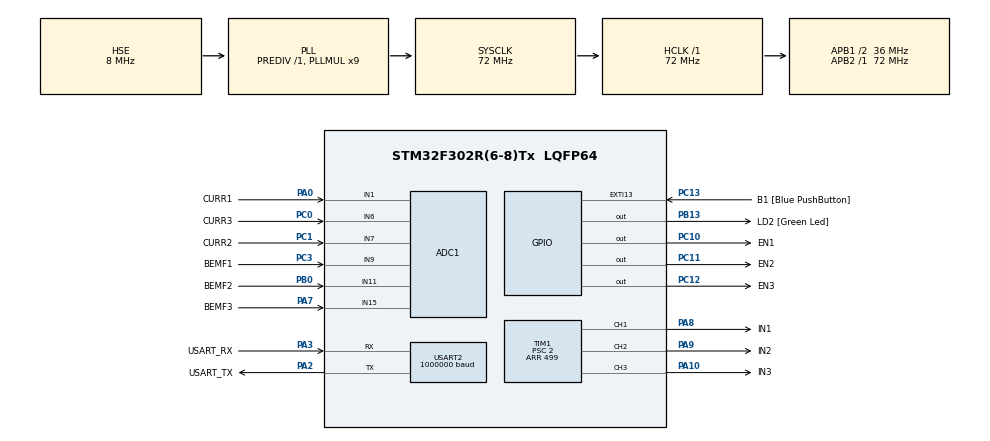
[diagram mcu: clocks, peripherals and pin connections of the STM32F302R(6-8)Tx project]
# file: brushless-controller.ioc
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ADC1.Channel-0\#ChannelRegularConversion=ADC_CHANNEL_9
ADC1.Channel-1\#ChannelRegularConversion=ADC_CHANNEL_11
ADC1.Channel-2\#ChannelRegularConversion=ADC_CHANNEL_15
ADC1.Channel-3\#ChannelRegularConversion=ADC_CHANNEL_1
ADC1.Channel-4\#ChannelRegularConversion=ADC_CHANNEL_7
ADC1.Channel-5\#ChannelRegularConversion=ADC_CHANNEL_6
ADC1.ClockPrescaler=ADC_CLOCK_ASYNC_DIV1
ADC1.ContinuousConvMode=DISABLE
ADC1.DMAContinuousRequests=ENABLE
ADC1.EOCSelection=ADC_EOC_SEQ_CONV
ADC1.EnableInjectedConversion=DISABLE
ADC1.NbrOfConversion=6
ADC1.NbrOfConversionFlag=1
ADC1.Offset-0\#ChannelRegularConversion=0
ADC1.Offset-1\#ChannelRegularConversion=0
ADC1.Offset-2\#ChannelRegularConversion=0
ADC1.Offset-3\#ChannelRegularConversion=0
ADC1.Offset-4\#ChannelRegularConversion=0
ADC1.Offset-5\#ChannelRegularConversion=0
ADC1.OffsetNumber-0\#ChannelRegularConversion=ADC_OFFSET_NONE
ADC1.OffsetNumber-1\#ChannelRegularConversion=ADC_OFFSET_NONE
ADC1.OffsetNumber-2\#ChannelRegularConversion=ADC_OFFSET_NONE
ADC1.OffsetNumber-3\#ChannelRegularConversion=ADC_OFFSET_NONE
ADC1.OffsetNumber-4\#ChannelRegularConversion=ADC_OFFSET_NONE
ADC1.OffsetNumber-5\#ChannelRegularConversion=ADC_OFFSET_NONE
ADC1.Rank-0\#ChannelRegularConversion=1
ADC1.Rank-1\#ChannelRegularConversion=2
ADC1.Rank-2\#ChannelRegularConversion=3
ADC1.Rank-3\#ChannelRegularConversion=4
ADC1.Rank-4\#ChannelRegularConversion=5
ADC1.Rank-5\#ChannelRegularConversion=6
ADC1.SamplingTime-0\#ChannelRegularConversion=ADC_SAMPLETIME_1CYCLE_5
ADC1.SamplingTime-1\#ChannelRegularConversion=ADC_SAMPLETIME_1CYCLE_5
ADC1.SamplingTime-2\#ChannelRegularConversion=ADC_SAMPLETIME_1CYCLE_5
ADC1.SamplingTime-3\#ChannelRegularConversion=ADC_SAMPLETIME_1CYCLE_5
ADC1.SamplingTime-4\#ChannelRegularConversion=ADC_SAMPLETIME_1CYCLE_5
ADC1.SamplingTime-5\#ChannelRegularConversion=ADC_SAMPLETIME_1CYCLE_5
ADC1.SamplingTimeOPAMP-1\#ChannelRegularConversion=ADC_SAMPLETIME_61CYCLES_5
ADC1.SamplingTimeOPAMP-2\#ChannelRegularConversion=ADC_SAMPLETIME_61CYCLES_5
ADC1.SamplingTimeOPAMP-3\#ChannelRegularConversion=ADC_SAMPLETIME_61CYCLES_5
ADC1.SamplingTimeOPAMP-4\#ChannelRegularConversion=ADC_SAMPLETIME_61CYCLES_5
ADC1.SamplingTimeOPAMP-5\#ChannelRegularConversion=ADC_SAMPLETIME_61CYCLES_5
ADC1.SequencerNbRanks=0
ADC1.SubFamily=STM32F302x8
ADC1.master=1
Dma.ADC1.2.Direction=DMA_PERIPH_TO_MEMORY
Dma.ADC1.2.Instance=DMA1_Channel1
Dma.ADC1.2.MemDataAlignment=DMA_MDATAALIGN_HALFWORD
Dma.ADC1.2.MemInc=DMA_MINC_ENABLE
Dma.ADC1.2.Mode=DMA_NORMAL
Dma.ADC1.2.PeriphDataAlignment=DMA_PDATAALIGN_HALFWORD
Dma.ADC1.2.PeriphInc=DMA_PINC_DISABLE
Dma.ADC1.2.Priority=DMA_PRIORITY_LOW
Dma.Request0=USART2_RX
Dma.Request1=USART2_TX
Dma.Request2=ADC1
Dma.USART2_RX.0.Direction=DMA_PERIPH_TO_MEMORY
Dma.USART2_RX.0.Instance=DMA1_Channel6
Dma.USART2_RX.0.MemDataAlignment=DMA_MDATAALIGN_BYTE
Dma.USART2_RX.0.MemInc=DMA_MINC_ENABLE
Dma.USART2_RX.0.Mode=DMA_CIRCULAR
Dma.USART2_RX.0.PeriphDataAlignment=DMA_PDATAALIGN_BYTE
Dma.USART2_RX.0.PeriphInc=DMA_PINC_DISABLE
Dma.USART2_RX.0.Priority=DMA_PRIORITY_LOW
Dma.USART2_TX.1.Direction=DMA_MEMORY_TO_PERIPH
Dma.USART2_TX.1.Instance=DMA1_Channel7
Dma.USART2_TX.1.MemDataAlignment=DMA_MDATAALIGN_BYTE
Dma.USART2_TX.1.MemInc=DMA_MINC_ENABLE
Dma.USART2_TX.1.Mode=DMA_NORMAL
Dma.USART2_TX.1.PeriphDataAlignment=DMA_PDATAALIGN_BYTE
Dma.USART2_TX.1.PeriphInc=DMA_PINC_DISABLE
Dma.USART2_TX.1.Priority=DMA_PRIORITY_LOW
Mcu.Family=STM32F3
Mcu.Name=STM32F302R(6-8)Tx
Mcu.Package=LQFP64
NVIC.DMA1_Channel1_IRQn=true\:0\:0\:false\:false\:true\:false\:true\:true
NVIC.DMA1_Channel6_IRQn=true\:0\:0\:false\:false\:true\:false\:true\:true
NVIC.DMA1_Channel7_IRQn=true\:0\:0\:false\:false\:true\:false\:true\:true
NVIC.PriorityGroup=NVIC_PRIORITYGROUP_0
NVIC.TIM1_UP_TIM16_IRQn=true\:0\:0\:false\:false\:true\:true\:true\:true
NVIC.USART2_IRQn=true\:0\:0\:false\:false\:true\:true\:true\:true
PA0.GPIO_Label=CURR1
PA0.Mode=IN1-Single-Ended
PA0.Signal=ADC1_IN1
PA10.GPIO_Label=IN3
PA10.Signal=S_TIM1_CH3
PA13.GPIO_Label=TMS
PA13.Mode=Serial_Wire
PA13.Signal=SYS_JTMS-SWDIO
PA14.GPIO_Label=TCK
PA14.Mode=Serial_Wire
PA14.Signal=SYS_JTCK-SWCLK
PA2.GPIO_Label=USART_TX
PA2.GPIO_Mode=GPIO_MODE_AF_PP
PA2.GPIO_PuPd=GPIO_NOPULL
PA2.GPIO_Speed=GPIO_SPEED_FREQ_LOW
PA2.Mode=Asynchronous
PA2.Signal=USART2_TX
PA3.GPIO_Label=USART_RX
PA3.GPIO_Mode=GPIO_MODE_AF_PP
PA3.GPIO_PuPd=GPIO_NOPULL
PA3.GPIO_Speed=GPIO_SPEED_FREQ_LOW
PA3.Mode=Asynchronous
PA3.Signal=USART2_RX
PA7.GPIO_Label=BEMF3
PA7.Mode=IN15-Single-Ended
PA7.Signal=ADC1_IN15
PA8.GPIO_Label=IN1
PA8.Signal=S_TIM1_CH1
PA9.GPIO_Label=IN2
PA9.Signal=S_TIM1_CH2
PB0.GPIO_Label=BEMF2
PB0.Mode=IN11-Single-Ended
PB0.Signal=ADC1_IN11
PB13.GPIO_Label=LD2 [Green Led]
PB13.Signal=GPIO_Output
PB3.GPIO_Label=SWO
PB3.Mode=Trace_Asynchronous_SW
PB3.Signal=SYS_JTDO-TRACESWO
PC0.GPIO_Label=CURR3
PC0.Signal=ADCx_IN6
PC1.GPIO_Label=CURR2
PC1.Signal=ADCx_IN7
PC10.GPIO_Label=EN1
PC10.Signal=GPIO_Output
PC11.GPIO_Label=EN2
PC11.Signal=GPIO_Output
PC12.GPIO_Label=EN3
PC12.Signal=GPIO_Output
PC13.GPIO_Label=B1 [Blue PushButton]
PC13.GPIO_ModeDefaultEXTI=GPIO_MODE_IT_FALLING
PC13.Signal=GPXTI13
PC14\ -\ OSC32_IN.Mode=LSE-External-Oscillator
PC14\ -\ OSC32_IN.Signal=RCC_OSC32_IN
PC15\ -\ OSC32_OUT.Mode=LSE-External-Oscillator
PC15\ -\ OSC32_OUT.Signal=RCC_OSC32_OUT
PC3.GPIO_Label=BEMF1
PC3.Signal=ADCx_IN9
PF0-OSC_IN.Mode=HSE-External-Clock-Source
PF0-OSC_IN.Signal=RCC_OSC_IN
PF1-OSC_OUT.Signal=RCC_OSC_OUT
ProjectManager.HeapSize=0x200
ProjectManager.StackSize=0x400
ProjectManager.TargetToolchain=STM32CubeIDE
RCC.AHBFreq_Value=72000000
RCC.APB1CLKDivider=RCC_HCLK_DIV2
RCC.APB1Freq_Value=36000000
RCC.APB1TimFreq_Value=72000000
RCC.APB2Freq_Value=72000000
RCC.APB2TimFreq_Value=72000000
RCC.CortexFreq_Value=72000000
RCC.HCLKFreq_Value=72000000
RCC.HSE_VALUE=8000000
RCC.HSI_VALUE=8000000
RCC.PLLM=8
RCC.PLLMUL=RCC_PLL_MUL9
RCC.PLLN=336
RCC.PLLP=RCC_PLLP_DIV4
RCC.PLLQ=7
RCC.PLLSourceVirtual=RCC_PLLSOURCE_HSE
RCC.SYSCLKFreq_VALUE=72000000
RCC.SYSCLKSourceVirtual=RCC_SYSCLKSOURCE_PLLCLK
RCC.USBFreq_Value=72000000
SH.ADCx_IN6.0=ADC1_IN6,IN6-Single-Ended
SH.ADCx_IN7.0=ADC1_IN7,IN7-Single-Ended
SH.ADCx_IN9.0=ADC1_IN9,IN9-Single-Ended
SH.S_TIM1_CH1.0=TIM1_CH1,PWM Generation1 CH1
SH.S_TIM1_CH2.0=TIM1_CH2,PWM Generation2 CH2
SH.S_TIM1_CH3.0=TIM1_CH3,PWM Generation3 CH3
TIM1.AutoReloadPreload=TIM_AUTORELOAD_PRELOAD_ENABLE
TIM1.Channel-PWM\ Generation1\ CH1=TIM_CHANNEL_1
TIM1.Channel-PWM\ Generation2\ CH2=TIM_CHANNEL_2
TIM1.Channel-PWM\ Generation3\ CH3=TIM_CHANNEL_3
TIM1.CounterMode=TIM_COUNTERMODE_CENTERALIGNED3
TIM1.Period=499
TIM1.Prescaler=2
USART2.BaudRate=1000000
USART2.VirtualMode-Asynchronous=VM_ASYNC
VP_TIM1_VS_ClockSourceINT.Mode=Internal
board=NUCLEO-F302R8

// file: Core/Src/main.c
/* USER CODE BEGIN Header */
/**
  ******************************************************************************
  * @file           : main.c
  * @brief          : Main program body
  ******************************************************************************
  * @attention
  *
  * Copyright (c) 2024 STMicroelectronics.
  * All rights reserved.
  *
  * This software is licensed under terms that can be found in the LICENSE file
  * in the root directory of this software component.
  * If no LICENSE file comes with this software, it is provided AS-IS.
  *
  ******************************************************************************
  */
/* USER CODE END Header */
#include "main.h"
#include "adc.h"
#include "dma.h"
#include "tim.h"
#include "usart.h"
#include "gpio.h"

/* USER CODE BEGIN Includes */
#include "src_main.h"
/* USER CODE END Includes */

void SystemClock_Config(void);

int main(void)
{

  /* MCU Configuration--------------------------------------------------------*/

  /* Reset of all peripherals, Initializes the Flash interface and the Systick. */
  HAL_Init();

  /* Configure the system clock */
  SystemClock_Config();

  /* Initialize all configured peripherals */
  MX_GPIO_Init();
  MX_DMA_Init();
  MX_USART2_UART_Init();
  MX_ADC1_Init();
  MX_TIM1_Init();

  /* Infinite loop */
  /* USER CODE BEGIN WHILE */
  src_main(); // This blocks the program forever
  while (1)
  {
    /* USER CODE END WHILE */

  }
}

void SystemClock_Config(void)
{
  RCC_OscInitTypeDef RCC_OscInitStruct = {0};
  RCC_ClkInitTypeDef RCC_ClkInitStruct = {0};
  RCC_PeriphCLKInitTypeDef PeriphClkInit = {0};

  /** Initializes the RCC Oscillators according to the specified parameters
  * in the RCC_OscInitTypeDef structure.
  */
  RCC_OscInitStruct.OscillatorType = RCC_OSCILLATORTYPE_HSE;
  RCC_OscInitStruct.HSEState = RCC_HSE_BYPASS;
  RCC_OscInitStruct.HSEPredivValue = RCC_HSE_PREDIV_DIV1;
  RCC_OscInitStruct.HSIState = RCC_HSI_ON;
  RCC_OscInitStruct.PLL.PLLState = RCC_PLL_ON;
  RCC_OscInitStruct.PLL.PLLSource = RCC_PLLSOURCE_HSE;
  RCC_OscInitStruct.PLL.PLLMUL = RCC_PLL_MUL9;
  if (HAL_RCC_OscConfig(&RCC_OscInitStruct) != HAL_OK)
  {
    Error_Handler();
  }

  /** Initializes the CPU, AHB and APB buses clocks
  */
  RCC_ClkInitStruct.ClockType = RCC_CLOCKTYPE_HCLK|RCC_CLOCKTYPE_SYSCLK
                              |RCC_CLOCKTYPE_PCLK1|RCC_CLOCKTYPE_PCLK2;
  RCC_ClkInitStruct.SYSCLKSource = RCC_SYSCLKSOURCE_PLLCLK;
  RCC_ClkInitStruct.AHBCLKDivider = RCC_SYSCLK_DIV1;
  RCC_ClkInitStruct.APB1CLKDivider = RCC_HCLK_DIV2;
  RCC_ClkInitStruct.APB2CLKDivider = RCC_HCLK_DIV1;

  if (HAL_RCC_ClockConfig(&RCC_ClkInitStruct, FLASH_LATENCY_2) != HAL_OK)
  {
    Error_Handler();
  }
  PeriphClkInit.PeriphClockSelection = RCC_PERIPHCLK_TIM1|RCC_PERIPHCLK_ADC1;
  PeriphClkInit.Tim1ClockSelection = RCC_TIM1CLK_HCLK;
  PeriphClkInit.Adc1ClockSelection = RCC_ADC1PLLCLK_DIV1;

  if (HAL_RCCEx_PeriphCLKConfig(&PeriphClkInit) != HAL_OK)
  {
    Error_Handler();
  }
}

void Error_Handler(void)
{
  __disable_irq();
  while (1)
  {
  }
}
